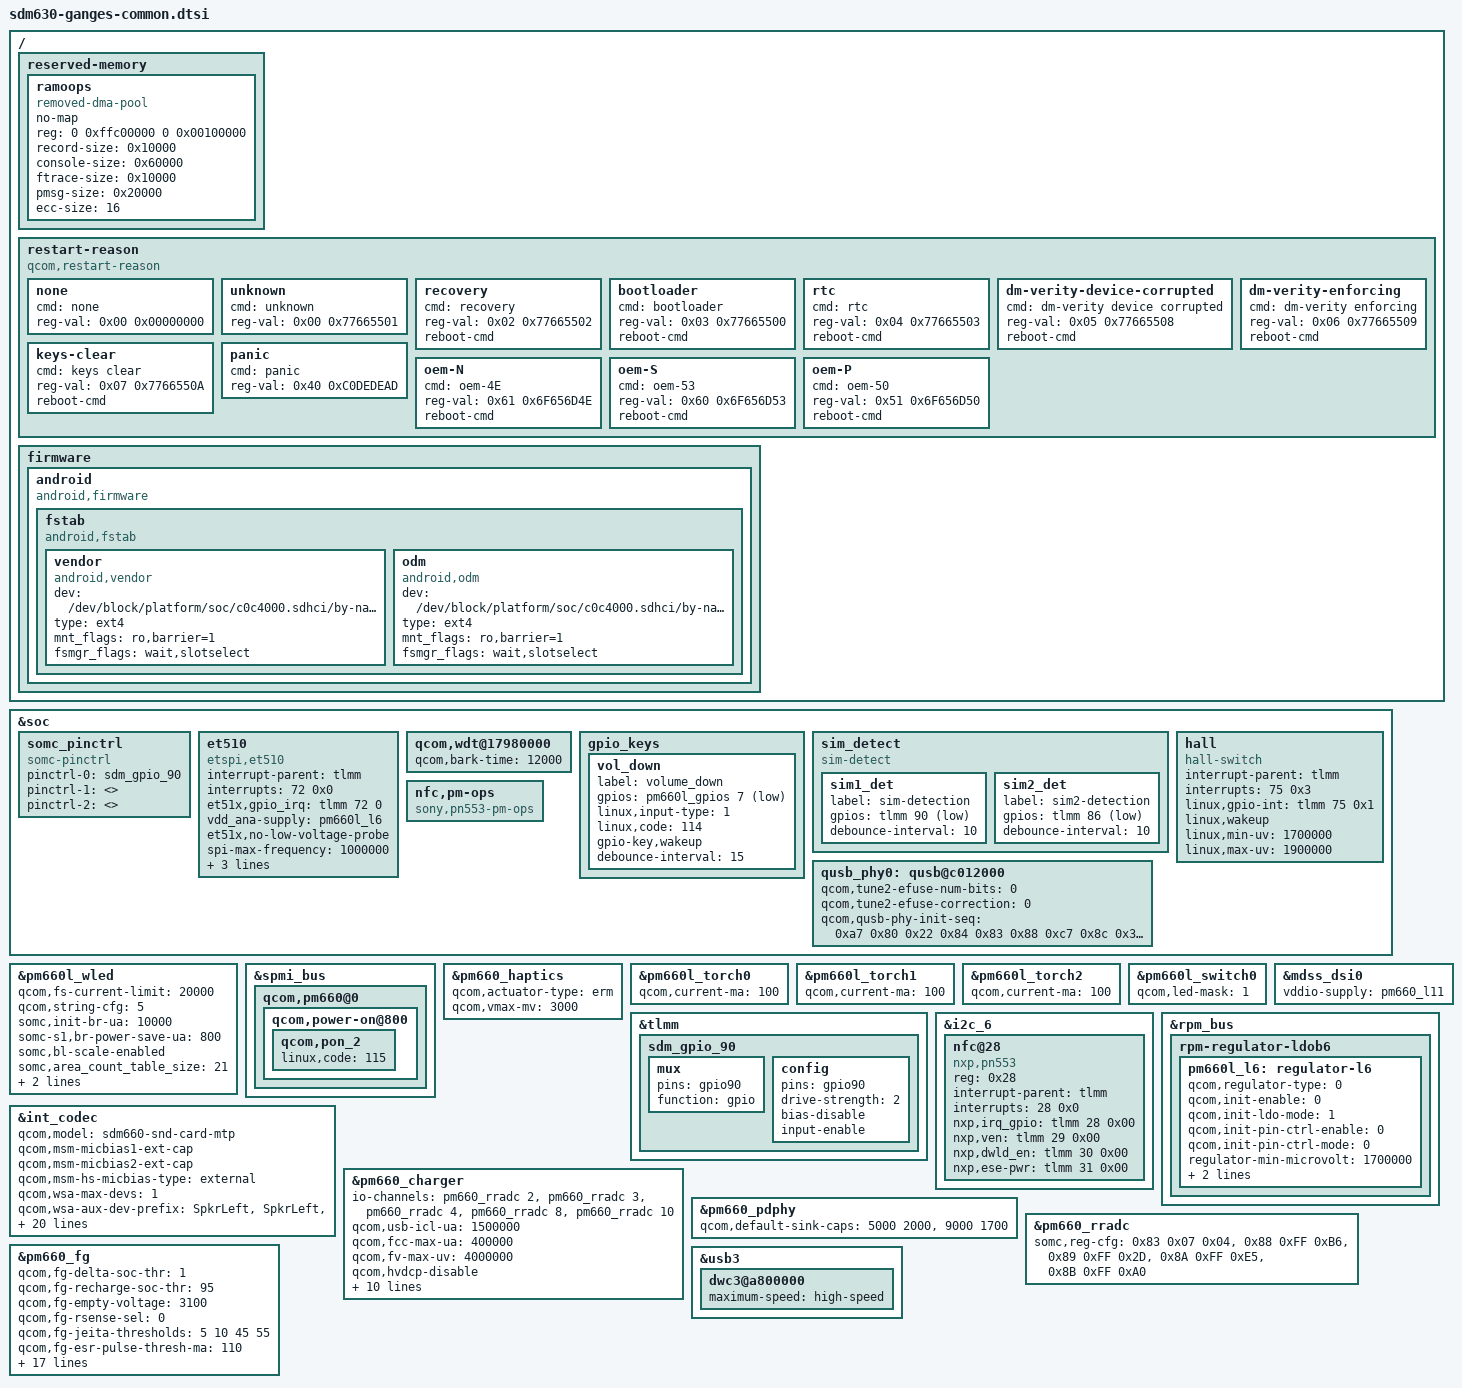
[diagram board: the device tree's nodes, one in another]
// SPDX-License-Identifier: GPL-2.0-only
/*
 * Copyright (c) 2019-2021, The Linux Foundation. All rights reserved.
 */

#include <dt-bindings/gpio/gpio.h>
#include "sdm630-ganges-pinctrl.dtsi"

/ {
	reserved-memory {
		ramoops {
			compatible = "removed-dma-pool", "ramoops";
			no-map;
			reg = <0 0xffc00000 0 0x00100000>;
			record-size = <0x10000>;
			console-size = <0x60000>;
			ftrace-size = <0x10000>;
			pmsg-size = <0x20000>;
			ecc-size = <16>;
		};
	};

	restart-reason {
		compatible = "qcom,restart-reason";

		none {
			cmd = "none";
			reg-val = <0x00 0x00000000>;
		};

		unknown {
			cmd = "unknown";
			reg-val = <0x00 0x77665501>;
		};

		recovery {
			cmd = "recovery";
			reg-val = <0x02 0x77665502>;
			reboot-cmd;
		};

		bootloader {
			cmd = "bootloader";
			reg-val = <0x03 0x77665500>;
			reboot-cmd;
		};

		rtc {
			cmd = "rtc";
			reg-val = <0x04 0x77665503>;
			reboot-cmd;
		};

		dm-verity-device-corrupted {
			cmd = "dm-verity device corrupted";
			reg-val = <0x05 0x77665508>;
			reboot-cmd;
		};

		dm-verity-enforcing {
			cmd = "dm-verity enforcing";
			reg-val = <0x06 0x77665509>;
			reboot-cmd;
		};

		keys-clear {
			cmd = "keys clear";
			reg-val = <0x07 0x7766550A>;
			reboot-cmd;
		};

		panic {
			cmd = "panic";
			reg-val = <0x40 0xC0DEDEAD>;
		};

		oem-N {
			cmd = "oem-4E";
			reg-val = <0x61 0x6F656D4E>;
			reboot-cmd;
		};

		oem-S {
			cmd = "oem-53";
			reg-val = <0x60 0x6F656D53>;
			reboot-cmd;
		};

		oem-P {
			cmd = "oem-50";
			reg-val = <0x51 0x6F656D50>;
			reboot-cmd;
		};
	};

	firmware: firmware {
		android {
			compatible = "android,firmware";

			fstab {
				compatible = "android,fstab";

				vendor {
					compatible = "android,vendor";
					dev = "/dev/block/platform/soc/c0c4000.sdhci/by-name/vendor";
					type = "ext4";
					mnt_flags = "ro,barrier=1";
					fsmgr_flags = "wait,slotselect";
					status = "ok";
				};

				odm {
					compatible = "android,odm";
					dev = "/dev/block/platform/soc/c0c4000.sdhci/by-name/oem";
					type = "ext4";
					mnt_flags = "ro,barrier=1";
					fsmgr_flags = "wait,slotselect";
					status = "ok";
				};
			};
		};
	};
};

&soc {
	somc_pinctrl: somc_pinctrl {
		compatible = "somc-pinctrl";
		pinctrl-names = "platform_common_default",
				"product_common_default",
				"variant_default";
		pinctrl-0 = <&sdm_gpio_90>;

		/* If product common default setting is needed,
		fill pinctrl-1 value in <product>_common.dtsi */
		pinctrl-1 = <>;

		/* If variant specific default setting is needed,
		fill pinctrl-2 value in <variant>.dtsi */
		pinctrl-2 = <>;
	};

	et510 {
		compatible = "etspi,et510";
		interrupt-parent = <&tlmm>;
		interrupts = <72 0x0>;
		et51x,gpio_irq = <&tlmm 72 0>;
		vdd_ana-supply = <&pm660l_l6>;
		et51x,no-low-voltage-probe;

		spi-max-frequency = <1000000>;

		pinctrl-names = "et51x_reset_reset",
			"et51x_reset_active",
			"et51x_irq_active";
		pinctrl-0 = <&msm_gpio_20>;
		pinctrl-1 = <&msm_gpio_20_output_high>;
		pinctrl-2 = <&msm_gpio_72>;
	};

	qcom,wdt@17980000 {
		qcom,bark-time = <12000>;
	};

	gpio_keys {
		/delete-node/vol_up;
		vol_down {
			label = "volume_down";
			gpios = <&pm660l_gpios 7 0x1>;
			linux,input-type = <1>;
			linux,code = <114>;
			gpio-key,wakeup;
			debounce-interval = <15>;
		};
	};

	sim_detect {
		compatible = "sim-detect";

		sim1_det {
			label = "sim-detection";
			gpios = <&tlmm 90 GPIO_ACTIVE_LOW>;
			debounce-interval = <10>;
		};
		sim2_det {
			label = "sim2-detection";
			gpios = <&tlmm 86 GPIO_ACTIVE_LOW>;
			debounce-interval = <10>;
		};
	};

	hall {
		compatible = "hall-switch";
		interrupt-parent = <&tlmm>;
		interrupts = <75 0x3>;
		//vddio-supply = <&pm660l_l14>;
		linux,gpio-int = <&tlmm 75 0x1>;
		linux,wakeup;
		linux,min-uv = <1700000>;
		linux,max-uv = <1900000>;
	};

	qusb_phy0: qusb@c012000 {
		qcom,tune2-efuse-num-bits = <0>;
		qcom,tune2-efuse-correction = <0>;
		qcom,qusb-phy-init-seq = <0xa7 0x80
			0x22 0x84
			0x83 0x88
			0xc7 0x8c
			0x30 0x08
			0x79 0x0c
			0x21 0x10
			0x14 0x9c
			0x9f 0x1c
			0x00 0x18>;
	};

	nfc,pm-ops {
		compatible = "sony,pn553-pm-ops";
	};
};

&pm660l_wled {
	qcom,fs-current-limit = <20000>;
	qcom,string-cfg = <5>;

	/* Bootloader only properties */
	somc,init-br-ua = <10000>;
	somc-s1,br-power-save-ua = <800>;
	somc,bl-scale-enabled;
	somc,area_count_table_size = <21>;
	somc,area_count_table = <0 137 273 410 546 683 819 956
				1092 1229 1365 1638 1911 2184 2457
				2730 3003 3276 3549 3822 4095>;
};

&spmi_bus {
	qcom,pm660@0 {
		qcom,power-on@800 {
			qcom,pon_2 {
			linux,code = <115>;
			};
		};
	};
};

/* PM660 */
&pm660_haptics {
	qcom,actuator-type = "erm";
	qcom,vmax-mv = <3000>;
};

/* PM660L */
&pm660l_torch0 {
	qcom,current-ma = <100>;
};

&pm660l_torch1 {
	qcom,current-ma = <100>;
};

&pm660l_torch2 {
	qcom,current-ma = <100>;
};

&pm660l_switch0 {
	qcom,led-mask = <1>;
};

&mdss_dsi0 {
	vddio-supply = <&pm660_l11>;
};

&tlmm {
	/* GPIO_90: UIM1_PRESENT */
	sdm_gpio_90: sdm_gpio_90 {
		mux {
			pins = "gpio90";
			function = "gpio";
		};

		config {
			pins = "gpio90";
			drive-strength = <2>;
			bias-disable;
			input-enable;
		};
	};
};

&i2c_6 {
	/delete-node/nq@28;

	nfc@28 {
		compatible = "nxp,pn553";
		reg = <0x28>;
		interrupt-parent = <&tlmm>;
		interrupts = <28 0x0>;
		nxp,irq_gpio = <&tlmm 28 0x00>;
		nxp,ven = <&tlmm 29 0x00>;
		nxp,dwld_en = <&tlmm 30 0x00>;
		nxp,ese-pwr = <&tlmm 31 0x00>;
	};
};

&int_codec {
	status = "ok";
	qcom,model = "sdm660-snd-card-mtp";
	qcom,msm-micbias1-ext-cap;
	qcom,msm-micbias2-ext-cap;
	qcom,msm-hs-micbias-type = "external";

	qcom,wsa-max-devs = <1>;
	qcom,wsa-aux-dev-prefix = "SpkrLeft", "SpkrLeft",
				  "SpkrLeft", "SpkrLeft";

	qcom,audio-routing =
		"RX_BIAS", "INT_MCLK0",
		"SPK_RX_BIAS", "INT_MCLK0",
		"INT_LDO_H", "INT_MCLK0",
		"RX_I2S_CLK", "INT_MCLK0",
		"TX_I2S_CLK", "INT_MCLK0",
		"MIC BIAS External", "Handset Mic",
		"MIC BIAS External2", "Headset Mic",
		"MIC BIAS External", "Secondary Mic",
		"AMIC1", "MIC BIAS External",
		"AMIC2", "MIC BIAS External2",
		"AMIC3", "MIC BIAS External",
		"DMIC1", "MIC BIAS External",
		"MIC BIAS External", "Digital Mic1",
		"DMIC2", "MIC BIAS External",
		"MIC BIAS External", "Digital Mic2",
		"DMIC3", "MIC BIAS External",
		"MIC BIAS External", "Digital Mic3",
		"DMIC4", "MIC BIAS External",
		"MIC BIAS External", "Digital Mic4",
		"SpkrLeft IN", "SPK1 OUT",
		"SpkrRight IN", "SPK2 OUT",
		"PDM_IN_RX1", "PDM_OUT_RX1",
		"PDM_IN_RX2", "PDM_OUT_RX2",
		"PDM_IN_RX3", "PDM_OUT_RX3",
		"ADC1_IN", "ADC1_OUT",
		"ADC2_IN", "ADC2_OUT",
		"ADC3_IN", "ADC3_OUT";
};

&rpm_bus {
	rpm-regulator-ldob6 {
		status = "okay";
		pm660l_l6: regulator-l6 {
			qcom,regulator-type = <0>;  /* LDO */
			qcom,init-enable = <0>;
			qcom,init-ldo-mode = <1>;
			qcom,init-pin-ctrl-enable = <0>;
			qcom,init-pin-ctrl-mode = <0>;
			regulator-min-microvolt = <1700000>;
			regulator-max-microvolt = <3300000>;
			qcom,init-voltage = <3300000>;
			status = "okay";
		};
	};
};

&pm660_charger {
	io-channels = <&pm660_rradc 2>,
			<&pm660_rradc 3>,
			<&pm660_rradc 4>,
			<&pm660_rradc 8>,
			<&pm660_rradc 10>;
	io-channel-names = "skin_temp",
			   "usbin_i",
			   "usbin_v",
			   "charger_temp",
			   "charger_temp_max";
	qcom,usb-icl-ua = <1500000>;
	qcom,fcc-max-ua = <400000>;
	qcom,fv-max-uv = <4000000>;
	qcom,hvdcp-disable;
	qcom,prechg-safety-time = <1>;
	qcom,fastchg-safety-time = <2>;
	qcom,otg-cl-ua = <500000>;
	somc,thermal-lo-volt-icl-ua =  <2000000 1500000 1500000
					1500000 1300000 1100000
					1100000 1000000  900000
					 900000  500000  200000
					 100000       0       0>;
	somc,thermal-hi-volt-icl-ua =  <1700000 1700000 1700000
					1700000 1500000 1500000
					1000000 1000000 1000000
					 600000  500000  200000
					 100000        0      0>;
	somc,fake-charging-temp-level = <13>;
	somc,product-icl-ua = <2000000>;
	somc,high-voltage-icl-ua = <1700000>;
};

&pm660_pdphy {
	qcom,default-sink-caps = <5000 2000>, /* 5V @ 2A */
				 <9000 1700>; /* 9V @ 1.7A */
};

&pm660_rradc {
	somc,reg-cfg =
	/* addr mask value */
	<0x83 0x07 0x04>, /* FG_ADC_RR_AUX_THERM_CFG */
	<0x88 0xFF 0xB6>, /* FG_ADC_RR_AUX_THERM_C1 */
	<0x89 0xFF 0x2D>, /* FG_ADC_RR_AUX_THERM_C2 */
	<0x8A 0xFF 0xE5>, /* FG_ADC_RR_AUX_THERM_C3 */
	<0x8B 0xFF 0xA0>; /* FG_ADC_RR_AUX_THERM_HALF_RANGE */
};

&pm660_fg {
	qcom,fg-delta-soc-thr = <1>;
	qcom,fg-recharge-soc-thr = <95>;
	qcom,fg-empty-voltage = <3100>;
	qcom,fg-rsense-sel = <0>;
	qcom,fg-jeita-thresholds = <5 10 45 55>;
	qcom,fg-esr-pulse-thresh-ma = <110>;
	qcom,slope-limit-temp-threshold = <100>;
	qcom,slope-limit-coeffs = <1 1 1 1>;
	qcom,fg-esr-tight-lt-filter-micro-pct = <30000>;
	qcom,fg-esr-broad-lt-filter-micro-pct = <30000>;
	qcom,cycle-counter-en;
	qcom,cl-start-capacity = <15>;
	qcom,cl-min-temp = <150>;
	qcom,cl-max-temp = <450>;
	qcom,fg-jeita-hyst-temp = <2>;
	qcom,hold-soc-while-full;
	qcom,cl-max-increment = <0>;
	qcom,cl-max-decrement = <20>;
	qcom,battery-thermal-coefficients = [c7 50 ff];
	qcom,fg-sys-term-current = <(-175)>;
	qcom,fg-chg-term-current = <150>;
	somc,jeita-step-use-real-temp;
	somc,jeita-batt-temp-correction = <0>;
};

&usb3 {
	dwc3@a800000 {
		maximum-speed = "high-speed";
	};
};
